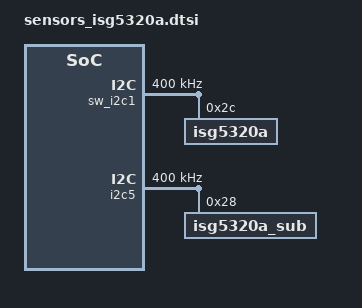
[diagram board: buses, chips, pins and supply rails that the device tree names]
#if 1

&sw_i2c1 {
	#address-cells = <1>;
	#size-cells = <0>;
	status = "okay";
	clock-frequency = <400000>;
	pinctrl-names = "default";
#if 1
	pinctrl-0 = <&grip_ldo_en>;
#endif

	isg5320a: isg5320a-i2c@2C {
		compatible = "isg5320a";
		status = "okay";
		reg = <0x2C>;
		pinctrl-names = "default";
		pinctrl-0 = <&grip_int>;

		interrupt-parent = <SEC_GPIO_TYPE(AP,pio,17)>;
		interrupts = <SEC_GPIO_NUM(AP,pio,17) 0>;

		isg5320a,irq-gpio = <SEC_GPIO_REF(AP,pio,17) 0>;
		isg5320a,hallic_detect = <1>;
		isg5320a,hallic_cert_detect = <1>;

		isg5320a,reg_num = <150>;
	};
};

&pio {
	grip_int: grip-int {
		pins_cmd_dat {
			pinmux = <MTK_PINMUX(SEC_GPIO_NUM(AP,pio,17), 0)>;
			slew-rate = <0>;
			bias-disable;
		};
	};
};

#if 1
&pio {
	grip_ldo_en: grip-ldo-en {
		pins_cmd_dat {
			pinmux = <MTK_PINMUX(SEC_GPIO_NUM(AP,pio,43), 0)>;
			slew-rate = <1>;
			bias-disable;
			output-high;
		};
	};
};
#endif

#if 0
&pio {
	grip_i2c: grip-i2c {
		pins_cmd0_dat {
			pinmux = <MTK_PINMUX(SEC_GPIO_NUM(AP,pio,152), 0)>;
			slew-rate = <0>;
			bias-disable;
		};
		pins_cmd1_dat {
			pinmux = <MTK_PINMUX(SEC_GPIO_NUM(AP,pio,165), 0)>;
			slew-rate = <0>;
			bias-disable;
		};
	};
};
#endif
#endif /*isg5320a*/



#if 1

&i2c5 {
	#address-cells = <1>;
	#size-cells = <0>;
	status = "okay";
	clock-frequency = <400000>;
	pinctrl-names = "default";
#if 0
	pinctrl-0 = <&grip_sub_ldo_en>;
#endif
	isg5320a_sub: isg5320a-sub-i2c@28 {
		compatible = "isg5320a_sub";
		status = "okay";
		reg = <0x28>;
		pinctrl-names = "default";
		pinctrl-0 = <&grip_sub_int>;

		interrupt-parent = <SEC_GPIO_TYPE(AP,pio,19)>;
		interrupts = <SEC_GPIO_NUM(AP,pio,19) 0>;

		isg5320a_sub,irq-gpio = <SEC_GPIO_REF(AP,pio,19) 0>;
		isg5320a_sub,hallic_detect = <1>;
		isg5320a_sub,hallic_cert_detect = <1>;

		isg5320a_sub,reg_num = <150>;
	};
};

&pio {
	grip_sub_int: grip-sub-int {
		pins_cmd_dat {
			pinmux = <MTK_PINMUX(SEC_GPIO_NUM(AP,pio,19), 0)>;
			slew-rate = <0>;
			bias-disable;
		};
	};
};

#if 0
&pio {
	grip_sub_ldo_en: grip-sub-ldo-en {
		pins_cmd_dat {
			pinmux = <MTK_PINMUX(SEC_GPIO_NUM(${gpio_grip_sub_en}), 0)>;
			slew-rate = <1>;
			bias-disable;
			output-high;
		};
	};
};
#endif

#if 0
&pio {
	grip_sub_i2c: grip-sub-i2c {
		pins_cmd0_dat {
			pinmux = <MTK_PINMUX(SEC_GPIO_NUM(AP,pio,49), 0)>;
			slew-rate = <0>;
			bias-disable;
		};
		pins_cmd1_dat {
			pinmux = <MTK_PINMUX(SEC_GPIO_NUM(AP,pio,48), 0)>;
			slew-rate = <0>;
			bias-disable;
		};
	};
};
#endif

#endif /*isg5320a_sub*/

/* /home/dpi/qb5_8814/workspace/P4_1716/android/kernel/kmodule/sensors/isg5320a/dts/isg5320a_mtk.a22.dtsi */
&isg5320a {
	isg5320a,set_reg = /bits/ 8 <
		0x05 0xFC
		0x06 0xF1
		0x07 0x13
		0x08 0x01
		0x09 0x80
		0x0A 0x20
		0x0B 0x00
		0x0C 0x00
		0x12 0x89
		0x19 0x8A
		0x1B 0x28
		0x1D 0x23
		0x1E 0x00
		0x1F 0x14
		0x20 0x05
		0x21 0x10
		0x22 0x10
		0x23 0x00
		0x24 0x00
		0x25 0x05
		0x26 0x05
		0x27 0x10
		0x28 0x23
		0x29 0x00
		0x2A 0x23
		0x2B 0x00
		0x2C 0x00
		0x2D 0x23
		0x2F 0x18
		0x30 0xC0
		0x41 0x11
		0x60 0x80
		0x61 0xB9
		0x62 0x0F
		0x63 0x00
		0x64 0x00
		0x65 0x44
		0x66 0x3C
		0x67 0x01
		0x68 0x00
		0x69 0x00
		0x6A 0x10
		0x6B 0x00
		0x6C 0x10
		0x6D 0x40
		0x6E 0x22
		0x6F 0x00
		0x70 0x01
		0x71 0x60
		0x72 0xFF
		0x73 0xFF
		0x74 0xFF
		0x7B 0x08
		0x7C 0x00
		0x7D 0x0C
		0x7E 0x00
		0x7F 0xF8
		0x80 0xF8
		0x81 0x00
		0x82 0xF0
		0x83 0xF0
		0x84 0xF0
		0x85 0xF0
		0x86 0xF0
		0x87 0xF0
		0x88 0x00
		0x89 0x00
		0x8A 0x08
		0x8B 0x00
		0x8C 0x02
		0x8D 0x00
		0x99 0x21
		0x9A 0x3C
		0x9B 0x01
		0x9C 0x5E
		0x9D 0x00
		0x9E 0x00
		0x9F 0x00
		0xA0 0x35
		0xA1 0xC0
		0xA2 0x22
		0xA3 0x00
		0xA4 0x08
		0xA5 0x60
		0xA6 0xFF
		0xA7 0xFF
		0xA8 0xFF
		0xA9 0x00
		0xAF 0x40
		0xB0 0x00
		0xB1 0x60
		0xB2 0x00
		0xB3 0xE0
		0xB4 0x60
		0xB5 0x28
		0xB6 0xFD
		0xB7 0x30
		0xB8 0xFD
		0xB9 0xE0
		0xBA 0x70
		0xBB 0x80
		0xBC 0xFF
		0xBD 0xFF
		0xBE 0x07
		0xBF 0xD0
		0xC0 0x00
		0xC1 0x73
		0xC2 0xF0
		0xC3 0x00
		0xC4 0x00
		0xC5 0x00
		0x13 0x3A
		0x18 0xF1
		0x1C 0x18
		0x35 0x00
		0x36 0x00
		0x3A 0x0A
		0x3B 0x50
		0x3C 0x0A
		0x3D 0x50
		0x3E 0x60
		0x94 0x10
		0x95 0xB8
		0x96 0x04
		0x2E 0x15
		0x0E 0xE0
		0x0F 0x1E
		0x10 0x40
		0x11 0xC1
		0xD0 0xE0
		0xD1 0x02
		0xD2 0x00
		0xD3 0xFF
		0xD4 0xFF
		0xD5 0x10
		0xD6 0x3C
		0xD7 0xFF
		0xD8 0x1E
		0xD9 0x78
		0xDA 0x7F
		0xDB 0xA0
		0xDC 0x00
		0x76 0x08
		0x77 0x00
		0x79 0x02
		0x7A 0x00
		0xAA 0x32
		0xAB 0xC8
		0xAD 0x04
		0xAE 0x00
		>;
};

&isg5320a_sub {
	isg5320a_sub,set_reg = /bits/ 8 <
		0x05 0xFC
		0x06 0xF1
		0x07 0x13
		0x08 0x01
		0x09 0x80
		0x0A 0x20
		0x0B 0x00
		0x0C 0x00
		0x12 0x89
		0x19 0x8A
		0x1B 0x1C
		0x1D 0x18
		0x1E 0x00
		0x1F 0x14
		0x20 0x05
		0x21 0x10
		0x22 0x10
		0x23 0x00
		0x24 0x00
		0x25 0x05
		0x26 0x05
		0x27 0x10
		0x28 0x18
		0x29 0x00
		0x2A 0x18
		0x2B 0x00
		0x2C 0x00
		0x2D 0x18
		0x2F 0x18
		0x30 0xC0
		0x41 0xFF
		0x60 0xF0
		0x61 0x95
		0x62 0x04
		0x63 0x00
		0x64 0x00
		0x65 0x44
		0x66 0x3C
		0x67 0x01
		0x68 0x00
		0x69 0x00
		0x6A 0x10
		0x6B 0x00
		0x6C 0x10
		0x6D 0x40
		0x6E 0x22
		0x6F 0x00
		0x70 0x01
		0x71 0x60
		0x72 0xFF
		0x73 0xFF
		0x74 0xFF
		0x7B 0x08
		0x7C 0x00
		0x7D 0x0C
		0x7E 0x00
		0x7F 0xF8
		0x80 0xF8
		0x81 0x00
		0x82 0xF0
		0x83 0xF0
		0x84 0xF0
		0x85 0xF0
		0x86 0xF0
		0x87 0xF0
		0x88 0x00
		0x89 0x00
		0x8A 0x08
		0x8B 0x00
		0x8C 0x02
		0x8D 0x00
		0x99 0x21
		0x9A 0x3C
		0x9B 0x01
		0x9C 0x18
		0x9D 0x00
		0x9E 0x00
		0x9F 0x00
		0xA0 0x2A
		0xA1 0xD0
		0xA2 0x22
		0xA3 0x00
		0xA4 0x08
		0xA5 0x60
		0xA6 0xFF
		0xA7 0xFF
		0xA8 0xFF
		0xA9 0x00
		0xAF 0x40
		0xB0 0x00
		0xB1 0x60
		0xB2 0x00
		0xB3 0xD8
		0xB4 0x60
		0xB5 0x28
		0xB6 0xFD
		0xB7 0x30
		0xB8 0xFD
		0xB9 0xE0
		0xBA 0x80
		0xBB 0x80
		0xBC 0x00
		0xBD 0x00
		0xBE 0x07
		0xBF 0xD0
		0xC0 0x00
		0xC1 0x73
		0xC2 0xF0
		0xC3 0x00
		0xC4 0x00
		0xC5 0x00
		0x13 0x3A
		0x18 0xF1
		0x1C 0x18
		0x35 0x00
		0x36 0x00
		0x3A 0x09
		0x3B 0x50
		0x3C 0x09
		0x3D 0x50
		0x3E 0x60
		0x94 0xE0
		0x95 0x98
		0x96 0x04
		0x2E 0x18
		0x0E 0xE0
		0x0F 0x1C
		0x10 0x40
		0x11 0xC1
		0xD0 0xE0
		0xD1 0x02
		0xD2 0x00
		0xD3 0xFF
		0xD4 0xFF
		0xD5 0x10
		0xD6 0x50
		0xD7 0xFF
		0xD8 0x1E
		0xD9 0x80
		0xDA 0x81
		0xDB 0xE0
		0xDC 0x00
		0x76 0x08
		0x77 0x00
		0x79 0x02
		0x7A 0x00
		0xAA 0x32
		0xAB 0xC8
		0xAD 0x04
		0xAE 0x00
		>;
};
